VERSION "EcuDiagSim 1.0"

NS_ :

BS_:

BU_: ABS ECM TCM BCM SRS IPC

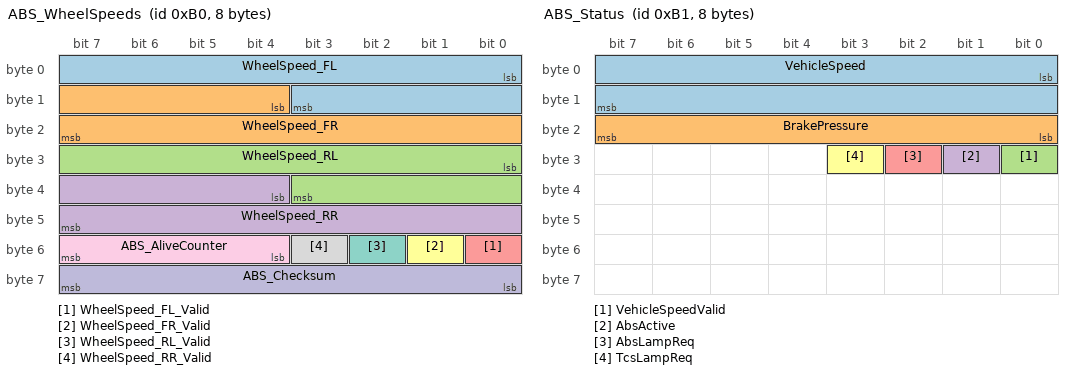
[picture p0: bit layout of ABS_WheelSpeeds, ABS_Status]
BO_ 176 ABS_WheelSpeeds: 8 ABS
 SG_ WheelSpeed_FL : 0|12@1+ (0.1,0) [0|409.5] "km/h" ECM,IPC
 SG_ WheelSpeed_FR : 12|12@1+ (0.1,0) [0|409.5] "km/h" ECM,IPC
 SG_ WheelSpeed_RL : 24|12@1+ (0.1,0) [0|409.5] "km/h" ECM,IPC
 SG_ WheelSpeed_RR : 36|12@1+ (0.1,0) [0|409.5] "km/h" ECM,IPC
 SG_ WheelSpeed_FL_Valid : 48|1@1+ (1,0) [0|1] "" ECM,IPC
 SG_ WheelSpeed_FR_Valid : 49|1@1+ (1,0) [0|1] "" ECM,IPC
 SG_ WheelSpeed_RL_Valid : 50|1@1+ (1,0) [0|1] "" ECM,IPC
 SG_ WheelSpeed_RR_Valid : 51|1@1+ (1,0) [0|1] "" ECM,IPC
 SG_ ABS_AliveCounter : 52|4@1+ (1,0) [0|15] "" ECM,IPC
 SG_ ABS_Checksum : 56|8@1+ (1,0) [0|255] "" ECM,IPC

BO_ 177 ABS_Status: 8 ABS
 SG_ VehicleSpeed : 0|16@1+ (0.01,0) [0|655.35] "km/h" ECM,TCM,BCM,IPC
 SG_ BrakePressure : 16|8@1+ (1,0) [0|255] "bar" ECM,TCM
 SG_ VehicleSpeedValid : 24|1@1+ (1,0) [0|1] "" ECM,TCM,BCM,IPC
 SG_ AbsActive : 25|1@1+ (1,0) [0|1] "" ECM,IPC
 SG_ AbsLampReq : 26|1@1+ (1,0) [0|1] "" IPC
 SG_ TcsLampReq : 27|1@1+ (1,0) [0|1] "" IPC

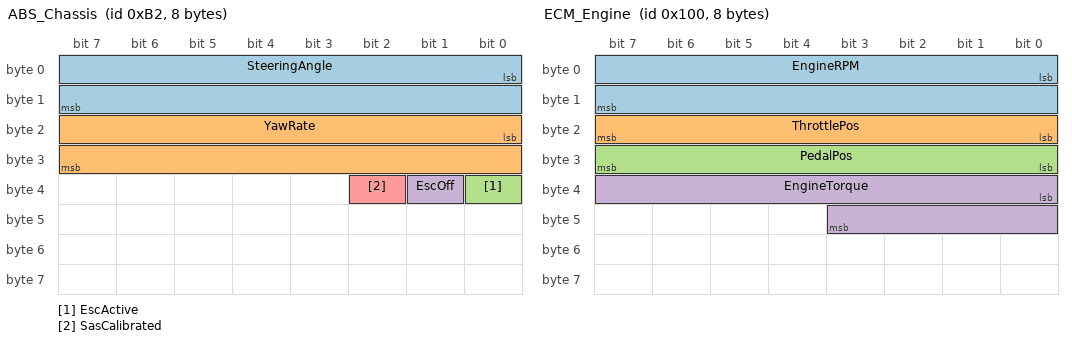
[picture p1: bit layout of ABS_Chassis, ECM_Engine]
BO_ 178 ABS_Chassis: 8 ABS
 SG_ SteeringAngle : 0|16@1+ (0.1,-3276.8) [-780|780] "deg" ECM,IPC
 SG_ YawRate : 16|16@1+ (0.01,-327.68) [-100|100] "deg/s" ECM,IPC
 SG_ EscActive : 32|1@1+ (1,0) [0|1] "" ECM,IPC
 SG_ EscOff : 33|1@1+ (1,0) [0|1] "" IPC
 SG_ SasCalibrated : 34|1@1+ (1,0) [0|1] "" IPC

BO_ 256 ECM_Engine: 8 ECM
 SG_ EngineRPM : 0|16@1+ (0.25,0) [0|16383.75] "rpm" TCM,ABS,IPC
 SG_ ThrottlePos : 16|8@1+ (0.4,0) [0|100] "%" TCM
 SG_ PedalPos : 24|8@1+ (0.4,0) [0|100] "%" TCM,ABS
 SG_ EngineTorque : 32|12@1+ (0.5,-500) [-500|1547.5] "Nm" TCM,ABS

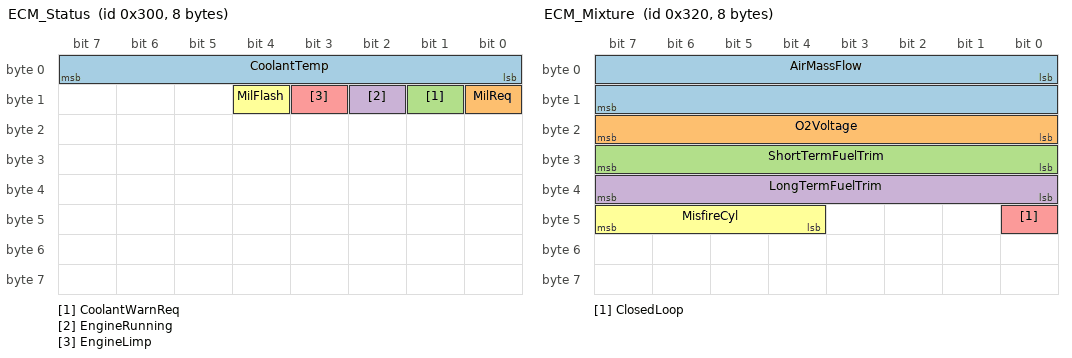
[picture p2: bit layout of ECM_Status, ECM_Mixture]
BO_ 768 ECM_Status: 8 ECM
 SG_ CoolantTemp : 0|8@1+ (1,-40) [-40|215] "degC" TCM,IPC
 SG_ MilReq : 8|1@1+ (1,0) [0|1] "" IPC
 SG_ CoolantWarnReq : 9|1@1+ (1,0) [0|1] "" IPC
 SG_ EngineRunning : 10|1@1+ (1,0) [0|1] "" TCM,ABS,BCM,IPC
 SG_ EngineLimp : 11|1@1+ (1,0) [0|1] "" IPC
 SG_ MilFlash : 12|1@1+ (1,0) [0|1] "" IPC

BO_ 800 ECM_Mixture: 8 ECM
 SG_ AirMassFlow : 0|16@1+ (0.01,0) [0|655.35] "g/s" IPC
 SG_ O2Voltage : 16|8@1+ (0.005,0) [0|1.275] "V" IPC
 SG_ ShortTermFuelTrim : 24|8@1+ (0.78125,-100) [-100|99.2] "%" IPC
 SG_ LongTermFuelTrim : 32|8@1+ (0.78125,-100) [-100|99.2] "%" IPC
 SG_ ClosedLoop : 40|1@1+ (1,0) [0|1] "" IPC
 SG_ MisfireCyl : 44|4@1+ (1,0) [0|15] "" IPC

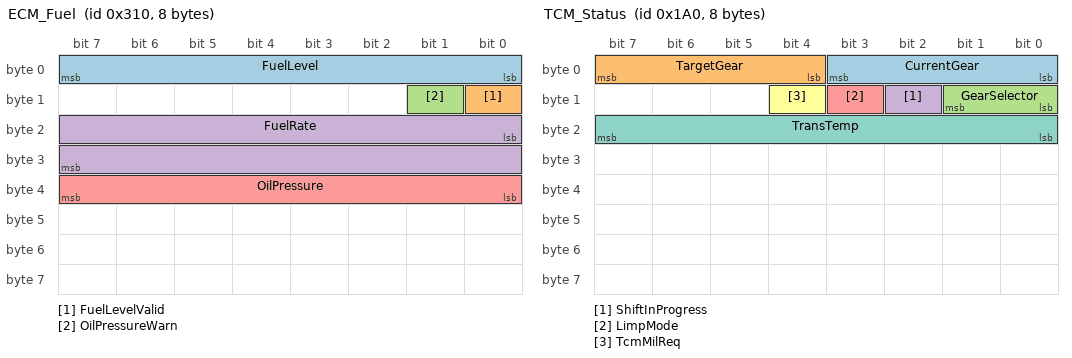
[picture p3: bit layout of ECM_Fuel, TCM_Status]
BO_ 784 ECM_Fuel: 8 ECM
 SG_ FuelLevel : 0|8@1+ (0.25,0) [0|63.75] "l" IPC
 SG_ FuelLevelValid : 8|1@1+ (1,0) [0|1] "" IPC
 SG_ OilPressureWarn : 9|1@1+ (1,0) [0|1] "" IPC
 SG_ FuelRate : 16|16@1+ (0.01,0) [0|655.35] "l/h" IPC
 SG_ OilPressure : 32|8@1+ (0.05,0) [0|12.75] "bar" IPC

BO_ 416 TCM_Status: 8 TCM
 SG_ CurrentGear : 0|4@1+ (1,0) [0|7] "" ECM,IPC
 SG_ TargetGear : 4|4@1+ (1,0) [0|7] "" ECM
 SG_ GearSelector : 8|2@1+ (1,0) [0|3] "" ECM,BCM,IPC
 SG_ ShiftInProgress : 10|1@1+ (1,0) [0|1] "" ECM
 SG_ LimpMode : 11|1@1+ (1,0) [0|1] "" ECM,IPC
 SG_ TcmMilReq : 12|1@1+ (1,0) [0|1] "" ECM
 SG_ TransTemp : 16|8@1+ (1,-40) [-40|215] "degC" ECM,IPC

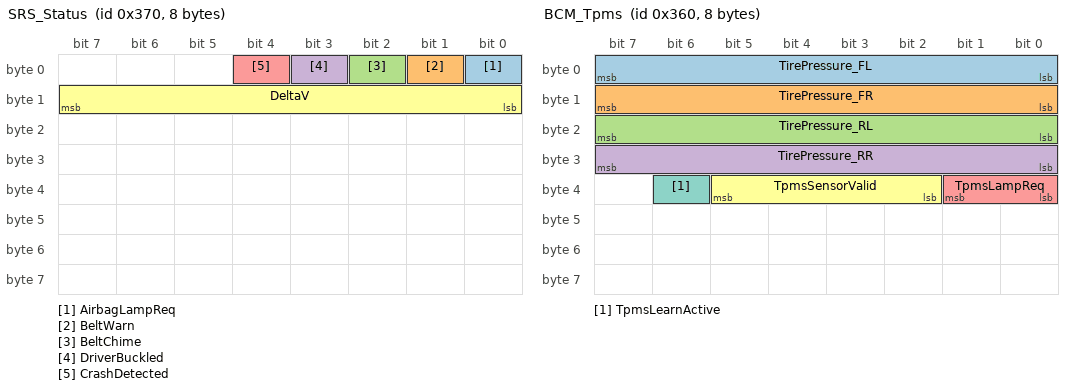
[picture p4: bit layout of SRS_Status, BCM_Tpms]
BO_ 880 SRS_Status: 8 SRS
 SG_ AirbagLampReq : 0|1@1+ (1,0) [0|1] "" IPC
 SG_ BeltWarn : 1|1@1+ (1,0) [0|1] "" IPC
 SG_ BeltChime : 2|1@1+ (1,0) [0|1] "" IPC
 SG_ DriverBuckled : 3|1@1+ (1,0) [0|1] "" IPC
 SG_ CrashDetected : 4|1@1+ (1,0) [0|1] "" ECM,BCM,IPC
 SG_ DeltaV : 8|8@1+ (1,0) [0|255] "km/h" IPC

BO_ 864 BCM_Tpms: 8 BCM
 SG_ TirePressure_FL : 0|8@1+ (0.02,0) [0|5.1] "bar" IPC
 SG_ TirePressure_FR : 8|8@1+ (0.02,0) [0|5.1] "bar" IPC
 SG_ TirePressure_RL : 16|8@1+ (0.02,0) [0|5.1] "bar" IPC
 SG_ TirePressure_RR : 24|8@1+ (0.02,0) [0|5.1] "bar" IPC
 SG_ TpmsLampReq : 32|2@1+ (1,0) [0|2] "" IPC
 SG_ TpmsSensorValid : 34|4@1+ (1,0) [0|15] "" IPC
 SG_ TpmsLearnActive : 38|1@1+ (1,0) [0|1] "" IPC

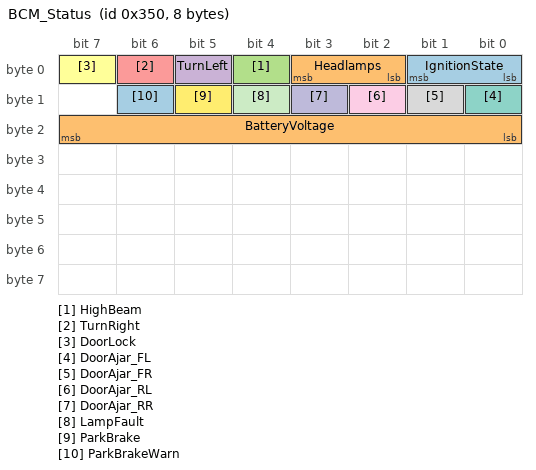
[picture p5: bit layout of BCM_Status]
BO_ 848 BCM_Status: 8 BCM
 SG_ IgnitionState : 0|2@1+ (1,0) [0|2] "" ECM,TCM,ABS,IPC
 SG_ Headlamps : 2|2@1+ (1,0) [0|2] "" IPC
 SG_ HighBeam : 4|1@1+ (1,0) [0|1] "" IPC
 SG_ TurnLeft : 5|1@1+ (1,0) [0|1] "" IPC
 SG_ TurnRight : 6|1@1+ (1,0) [0|1] "" IPC
 SG_ DoorLock : 7|1@1+ (1,0) [0|1] "" IPC
 SG_ DoorAjar_FL : 8|1@1+ (1,0) [0|1] "" IPC
 SG_ DoorAjar_FR : 9|1@1+ (1,0) [0|1] "" IPC
 SG_ DoorAjar_RL : 10|1@1+ (1,0) [0|1] "" IPC
 SG_ DoorAjar_RR : 11|1@1+ (1,0) [0|1] "" IPC
 SG_ LampFault : 12|1@1+ (1,0) [0|1] "" IPC
 SG_ ParkBrake : 13|1@1+ (1,0) [0|1] "" IPC
 SG_ ParkBrakeWarn : 14|1@1+ (1,0) [0|1] "" IPC
 SG_ BatteryVoltage : 16|8@1+ (0.1,0) [0|25.5] "V" ECM,IPC

CM_ BO_ 176 "Wheel speeds, 10 ms. Protected end-to-end by an alive counter and a CRC-8 (SAE J1850) over bytes 0..6.";
CM_ BO_ 177 "ABS vehicle speed and lamp requests, 20 ms.";
CM_ BO_ 178 "Stability control, 20 ms (only with ESC). EscActive: the ECM reduces the engine torque.";
CM_ BO_ 256 "Fast engine data, 10 ms.";
CM_ BO_ 768 "Slow engine data and lamp requests, 100 ms.";
CM_ BO_ 800 "Mixture control (engine OBD pack only), 100 ms.";
CM_ SG_ 800 MisfireCyl "Bit n-1 set: cylinder n misfires";
CM_ SG_ 768 MilFlash "Catalyst-damaging misfire: the MIL flashes";
CM_ BO_ 784 "Fuel and oil: tank level from the fuel sender, fuel rate, oil pressure, 100 ms.";
CM_ BO_ 416 "Transmission status, 20 ms.";
CM_ BO_ 880 "Airbag module status, 100 ms (only with the airbag system).";
CM_ SG_ 880 CrashDetected "Airbags fired in this ignition cycle: ECM cuts the fuel, BCM unlocks and switches the hazards on";
CM_ BO_ 864 "Tyre pressures from the TPMS sensors, 500 ms (only with tyre pressure monitoring).";
CM_ SG_ 864 TpmsLampReq "0 = off, 1 = low pressure (lamp on), 2 = system fault (lamp flashes 60 s, then on)";
CM_ SG_ 864 TpmsSensorValid "Bit n: data from wheel n (0 FL, 1 FR, 2 RL, 3 RR) is current";
CM_ BO_ 848 "Body status, 100 ms. Sent permanently (BCM is on terminal 30).";
CM_ SG_ 416 CurrentGear "0 = no drive (P/N), 1..6 = forward gear, 7 = reverse";
CM_ SG_ 416 GearSelector "0 = P, 1 = R, 2 = N, 3 = D";
CM_ SG_ 848 IgnitionState "0 = off, 1 = on, 2 = start";
CM_ SG_ 848 Headlamps "0 = off, 1 = parking lights, 2 = low beam";
CM_ SG_ 784 FuelLevelValid "0 = fuel sender fault, the level is a substitute value";
CM_ SG_ 848 ParkBrakeWarn "Driving faster than 10 km/h with the park brake applied";

BA_DEF_ BO_ "GenMsgCycleTime" INT 0 10000;
BA_DEF_DEF_ "GenMsgCycleTime" 0;
BA_ "GenMsgCycleTime" BO_ 176 10;
BA_ "GenMsgCycleTime" BO_ 177 20;
BA_ "GenMsgCycleTime" BO_ 178 20;
BA_ "GenMsgCycleTime" BO_ 256 10;
BA_ "GenMsgCycleTime" BO_ 768 100;
BA_ "GenMsgCycleTime" BO_ 784 100;
BA_ "GenMsgCycleTime" BO_ 800 100;
BA_ "GenMsgCycleTime" BO_ 416 20;
BA_ "GenMsgCycleTime" BO_ 848 100;
BA_ "GenMsgCycleTime" BO_ 864 500;
BA_ "GenMsgCycleTime" BO_ 880 100;

VAL_ 416 CurrentGear 0 "None" 1 "1" 2 "2" 3 "3" 4 "4" 5 "5" 6 "6" 7 "R";
VAL_ 416 GearSelector 0 "P" 1 "R" 2 "N" 3 "D";
VAL_ 848 IgnitionState 0 "Off" 1 "On" 2 "Start";
VAL_ 848 Headlamps 0 "Off" 1 "Park" 2 "Low";
